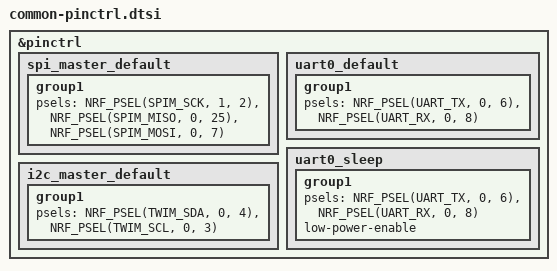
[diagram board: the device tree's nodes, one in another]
/*
 * Pin control configuration for chronos-ble-uart project
 * This file defines how pins are multiplexed for different peripherals
 * 
 * Pin assignments based on your main.c:
 * - SPI: SCK=P1.02, MOSI=P0.07, MISO=P0.25
 * - DAC1 CS: P0.16
 * - DAC2 CS: P0.26
 * - Control pins: P1.00, P1.01, P1.03
 */

&pinctrl {
    /* SPI Master configuration - matching your main.c */
    spi_master_default: spi_master_default {
        group1 {
            psels = <NRF_PSEL(SPIM_SCK, 1, 2)>,    /* P1.02 for SCK */
                    <NRF_PSEL(SPIM_MISO, 0, 25)>,  /* P0.25 for MISO */
                    <NRF_PSEL(SPIM_MOSI, 0, 7)>;    /* P0.07 for MOSI */
        };
    };

    /* UART pins for BLE NUS service */
    uart0_default: uart0_default {
        group1 {
            psels = <NRF_PSEL(UART_TX, 0, 6)>,     /* P0.06 - default TX pin */
                    <NRF_PSEL(UART_RX, 0, 8)>;      /* P0.08 - default RX pin */
        };
    };

    uart0_sleep: uart0_sleep {
        group1 {
            psels = <NRF_PSEL(UART_TX, 0, 6)>,
                    <NRF_PSEL(UART_RX, 0, 8)>;
            low-power-enable;
        };
    };

    /* I2C configurations - keeping for future use */
    i2c_master_default: i2c_master_default {
        group1 {
            psels = <NRF_PSEL(TWIM_SDA, 0, 4)>,    /* Example pins */
                    <NRF_PSEL(TWIM_SCL, 0, 3)>;
        };
    };
};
